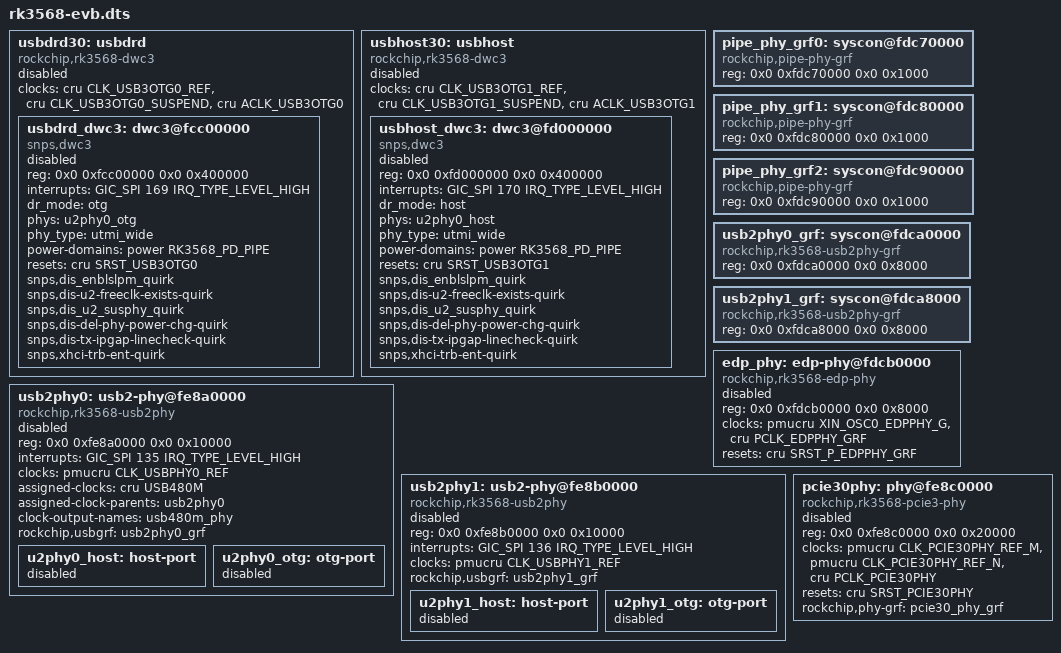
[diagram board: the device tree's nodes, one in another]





	usbdrd30: usbdrd {
		compatible = "rockchip,rk3568-dwc3", "rockchip,rk3399-dwc3";
		clocks = <&cru CLK_USB3OTG0_REF>, <&cru CLK_USB3OTG0_SUSPEND>,
			 <&cru ACLK_USB3OTG0>;
		clock-names = "ref_clk", "suspend_clk",
			      "bus_clk";
		#address-cells = <2>;
		#size-cells = <2>;
		ranges;
		status = "disabled";

		usbdrd_dwc3: dwc3@fcc00000 {
			compatible = "snps,dwc3";
			reg = <0x0 0xfcc00000 0x0 0x400000>;
			interrupts = <GIC_SPI 169 IRQ_TYPE_LEVEL_HIGH>;
			dr_mode = "otg";
			phys = <&u2phy0_otg>;
			phy-names = "usb2-phy";
			phy_type = "utmi_wide";
			power-domains = <&power RK3568_PD_PIPE>;
			resets = <&cru SRST_USB3OTG0>;
			reset-names = "usb3-otg";
			snps,dis_enblslpm_quirk;
			snps,dis-u2-freeclk-exists-quirk;
			snps,dis_u2_susphy_quirk;
			snps,dis-del-phy-power-chg-quirk;
			snps,dis-tx-ipgap-linecheck-quirk;
			snps,xhci-trb-ent-quirk;
			status = "disabled";
		};
	};

	usbhost30: usbhost {
		compatible = "rockchip,rk3568-dwc3", "rockchip,rk3399-dwc3";
		clocks = <&cru CLK_USB3OTG1_REF>, <&cru CLK_USB3OTG1_SUSPEND>,
			 <&cru ACLK_USB3OTG1>;
		clock-names = "ref_clk", "suspend_clk",
			      "bus_clk";
		#address-cells = <2>;
		#size-cells = <2>;
		ranges;
		status = "disabled";

		usbhost_dwc3: dwc3@fd000000 {
			compatible = "snps,dwc3";
			reg = <0x0 0xfd000000 0x0 0x400000>;
			interrupts = <GIC_SPI 170 IRQ_TYPE_LEVEL_HIGH>;
			dr_mode = "host";
			phys = <&u2phy0_host>;
			phy-names = "usb2-phy";
			phy_type = "utmi_wide";
			power-domains = <&power RK3568_PD_PIPE>;
			resets = <&cru SRST_USB3OTG1>;
			reset-names = "usb3-host";
			snps,dis_enblslpm_quirk;
			snps,dis-u2-freeclk-exists-quirk;
			snps,dis_u2_susphy_quirk;
			snps,dis-del-phy-power-chg-quirk;
			snps,dis-tx-ipgap-linecheck-quirk;
			snps,xhci-trb-ent-quirk;
			status = "disabled";
		};
	};




	pipe_phy_grf0: syscon@fdc70000 {
		compatible = "rockchip,pipe-phy-grf", "syscon";
		reg = <0x0 0xfdc70000 0x0 0x1000>;
	};

	pipe_phy_grf1: syscon@fdc80000 {
		compatible = "rockchip,pipe-phy-grf", "syscon";
		reg = <0x0 0xfdc80000 0x0 0x1000>;
	};

	pipe_phy_grf2: syscon@fdc90000 {
		compatible = "rockchip,pipe-phy-grf", "syscon";
		reg = <0x0 0xfdc90000 0x0 0x1000>;
	};

	usb2phy0_grf: syscon@fdca0000 {
		compatible = "rockchip,rk3568-usb2phy-grf", "syscon";
		reg = <0x0 0xfdca0000 0x0 0x8000>;
	};

	usb2phy1_grf: syscon@fdca8000 {
		compatible = "rockchip,rk3568-usb2phy-grf", "syscon";
		reg = <0x0 0xfdca8000 0x0 0x8000>;
	};

	edp_phy: edp-phy@fdcb0000 {
		compatible = "rockchip,rk3568-edp-phy";
		reg = <0x0 0xfdcb0000 0x0 0x8000>;
		clocks = <&pmucru XIN_OSC0_EDPPHY_G>, <&cru PCLK_EDPPHY_GRF>;
		clock-names = "refclk", "pclk";
		resets = <&cru SRST_P_EDPPHY_GRF>;
		reset-names = "apb";
		#phy-cells = <0>;
		status = "disabled";
	};



	usb2phy0: usb2-phy@fe8a0000 {
		compatible = "rockchip,rk3568-usb2phy";
		reg = <0x0 0xfe8a0000 0x0 0x10000>;
		interrupts = <GIC_SPI 135 IRQ_TYPE_LEVEL_HIGH>;
		clocks = <&pmucru CLK_USBPHY0_REF>;
		clock-names = "phyclk";
		#clock-cells = <0>;
		assigned-clocks = <&cru USB480M>;
		assigned-clock-parents = <&usb2phy0>;
		clock-output-names = "usb480m_phy";
		rockchip,usbgrf = <&usb2phy0_grf>;
		status = "disabled";

		u2phy0_host: host-port {
			#phy-cells = <0>;
			status = "disabled";
		};

		u2phy0_otg: otg-port {
			#phy-cells = <0>;
			status = "disabled";
		};
	};

	usb2phy1: usb2-phy@fe8b0000 {
		compatible = "rockchip,rk3568-usb2phy";
		reg = <0x0 0xfe8b0000 0x0 0x10000>;
		interrupts = <GIC_SPI 136 IRQ_TYPE_LEVEL_HIGH>;
		clocks = <&pmucru CLK_USBPHY1_REF>;
		clock-names = "phyclk";
		#clock-cells = <0>;
		rockchip,usbgrf = <&usb2phy1_grf>;
		status = "disabled";

		u2phy1_host: host-port {
			#phy-cells = <0>;
			status = "disabled";
		};

		u2phy1_otg: otg-port {
			#phy-cells = <0>;
			status = "disabled";
		};
	};

	pcie30phy: phy@fe8c0000 {
		compatible = "rockchip,rk3568-pcie3-phy";
		reg = <0x0 0xfe8c0000 0x0 0x20000>;
		#phy-cells = <0>;
		clocks = <&pmucru CLK_PCIE30PHY_REF_M>, <&pmucru CLK_PCIE30PHY_REF_N>,
			 <&cru PCLK_PCIE30PHY>;
		clock-names = "refclk_m", "refclk_n", "pclk";
		resets = <&cru SRST_PCIE30PHY>;
		reset-names = "phy";
		rockchip,phy-grf = <&pcie30_phy_grf>;
		status = "disabled";
	};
